# ADSP-SC83xW_HPC register map
Vendor: Analog Devices; Series: ADSP-SC83xW_HPC; File version: 3.0.3.517
CPU: 
Registers are 32-bit, read-write, reset 0x0 unless marked. A register's access mark holds for its fields unless they carry their own. Offsets are from the block's base; [hi:lo] are bit positions; 'fields as' and 'values as' point back to an identical list.

## PCG0 — Precision Clock Generator
Base 0x310C9000
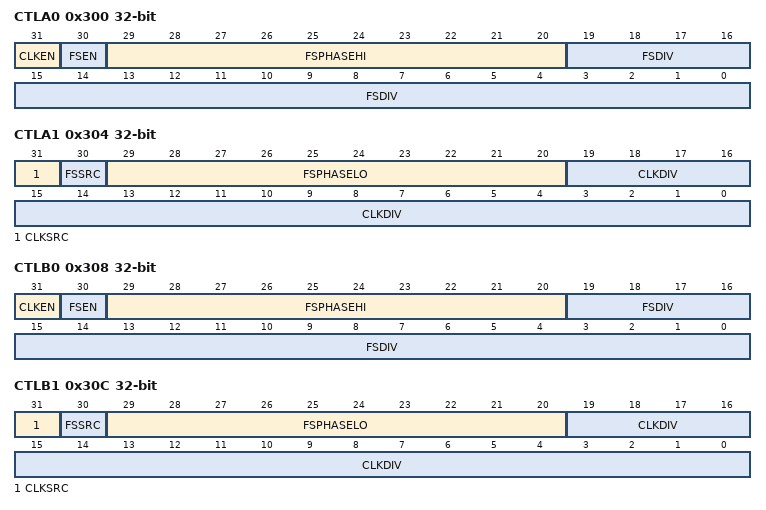
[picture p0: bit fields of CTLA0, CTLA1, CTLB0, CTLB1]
0x300 CTLA0 — Precision Clock A Control 0 Register
  [31] CLKEN — Clock Enable
  [30] FSEN — Frame Sync Enable
  [29:20] FSPHASEHI range 0x00000000..0x000003FF — Phase for Frame Sync High
  [19:0] FSDIV — Frame Sync Divider
0x304 CTLA1 — Precision Clock A Control 1 Register
  [31] CLKSRC — Clock Source
  [30] FSSRC — Frame Sync Source
  [29:20] FSPHASELO range 0x00000000..0x000003FF — Phase for Frame Sync Low
  [19:0] CLKDIV range 0x00000000..0x000FFFFF — Clock Divisor
0x308 CTLB0 — Precision Clock B Control 0 Register
  fields as CTLA0
0x30C CTLB1 — Precision Clock B Control 1 Register
  fields as CTLA1
0x310 PW1 — Precision Clock Pulse Width Control 1 Register
  [17] INVFSB range 0x00000000..0x00000001 — Active Low Frame Sync Select for Frame in Bypass PCG B
  [31:16] FSB range 0x00000000..0x0000FFFF — Pulse Width for Frame Sync PCG B
  [16] STROBEB range 0x00000000..0x00000001 — One Shot Frame Sync Bypass Mode PCG B
  [1] INVFSA range 0x00000000..0x00000001 — Active Low Frame Sync Select for Frame Sync in Bypass Mode
  [15:0] FSA range 0x00000000..0x0000FFFF — Pulse Width for Frame Sync PCG A
  [0] STROBEA range 0x00000000..0x00000001 — One Shot Frame Sync PCG A
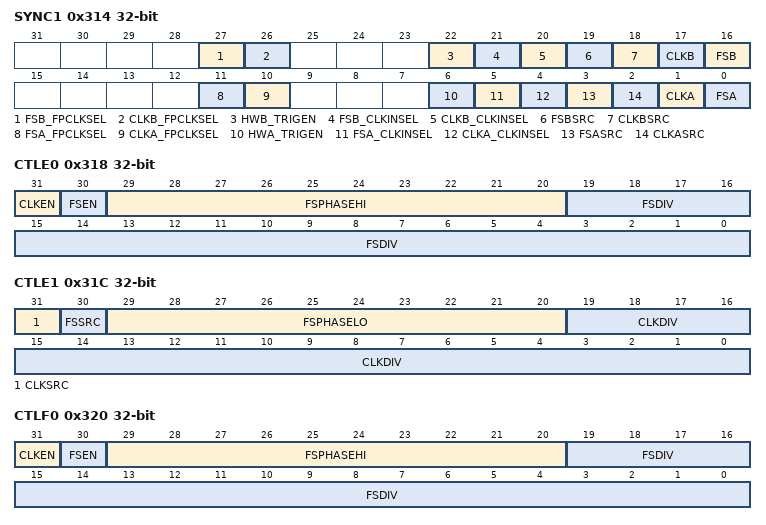
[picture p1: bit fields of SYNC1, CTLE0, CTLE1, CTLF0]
0x314 SYNC1 — Precision Clock Frame Sync Synchronization 1 Register
  [27] FSB_FPCLKSEL — Frame Sync B FracNPll Clock Select
  [26] CLKB_FPCLKSEL — Clock B FracNPll Clock Select
  [22] HWB_TRIGEN range 0x00000000..0x00000001 — Hardware Trigger Sync B Enable
  [21] FSB_CLKINSEL — CLKIN Source for FSB
  [20] CLKB_CLKINSEL — CLKIN Source for CLKB
  [19] FSBSRC — Frame Sync B Source
  [18] CLKBSRC — Clock B Source
  [17] CLKB — Clock B Enable
  [16] FSB — Frame Sync B Enable
  [11] FSA_FPCLKSEL — Frame Sync A FracNPll Clock Select
  [10] CLKA_FPCLKSEL — Clock A FracNPll Clock Select
  [6] HWA_TRIGEN range 0x00000000..0x00000001 — Hardware Trigger Sync A Enable
  [5] FSA_CLKINSEL — CLKIN Source for FSA
  [4] CLKA_CLKINSEL — CLKIN source for CLKA
  [3] FSASRC — Frame Sync Source
  [2] CLKASRC — Clock A Source
  [1] CLKA — Clock A Enable
  [0] FSA — Frame Sync A Enable
0x318 CTLE0 — Precision Clock E Control 0 Register
  fields as CTLA0
0x31C CTLE1 — Precision Clock E Control 1 Register
  fields as CTLA1
0x320 CTLF0 — Precision Clock F Control 0 Register
  fields as CTLA0
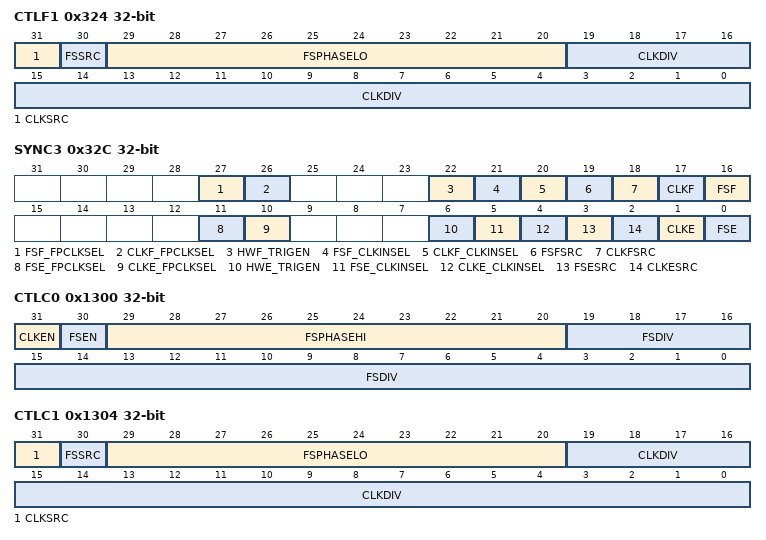
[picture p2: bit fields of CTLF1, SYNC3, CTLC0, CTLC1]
0x324 CTLF1 — Precision Clock F Control 1 Register
  fields as CTLA1
0x328 PW3 — Precision Clock Pulse Width Control 3 Register
  [17] INVFSF range 0x00000000..0x00000001 — Active Low Frame Sync Select for Frame Sync in Bypass Mode
  [31:16] FSF range 0x00000000..0x0000FFFF — Pulse Width for Frame Sync PCG F
  [16] STROBEF range 0x00000000..0x00000001 — One Shot Frame Sync PCG D
  [1] INVFSE range 0x00000000..0x00000001 — Active Low Frame Sync Select for Frame Sync in Bypass Mode
  [15:0] FSE range 0x00000000..0x0000FFFF — Pulse Width for Frame Sync PCG E
  [0] STROBEE range 0x00000000..0x00000001 — One Shot Frame Sync PCG E
0x32C SYNC3 — Precision Clock Frame Sync Synchronization 3 Register
  [27] FSF_FPCLKSEL — Frame Sync F FracNPll Clock Select
  [26] CLKF_FPCLKSEL — Clock F FracNPll Clock Select
  [22] HWF_TRIGEN range 0x00000000..0x00000001 — Hardware Trigger Sync F Enable
  [21] FSF_CLKINSEL — CLKIN Source for FSF
  [20] CLKF_CLKINSEL — CLKIN Source for CLKF
  [19] FSFSRC — Frame Sync F Source
  [18] CLKFSRC — Clock F Source
  [17] CLKF — Clock F Enable
  [16] FSF — Frame Sync F Enable
  [11] FSE_FPCLKSEL — Frame Sync E FracNPll Clock Select
  [10] CLKE_FPCLKSEL — Clock E FracNPll Clock Select
  [6] HWE_TRIGEN range 0x00000000..0x00000001 — Hardware Trigger Sync E Enable
  [5] FSE_CLKINSEL — CLKIN Source for FSE
  [4] CLKE_CLKINSEL — CLKIN Source for CLKE
  [3] FSESRC — Frame Sync Source
  [2] CLKESRC — Clock E Source
  [1] CLKE — Clock E Enable
  [0] FSE — Frame Sync E Enable
0x1300 CTLC0 — Precision Clock C Control 0 Register
  fields as CTLA0
0x1304 CTLC1 — Precision Clock C Control 1 Register
  fields as CTLA1
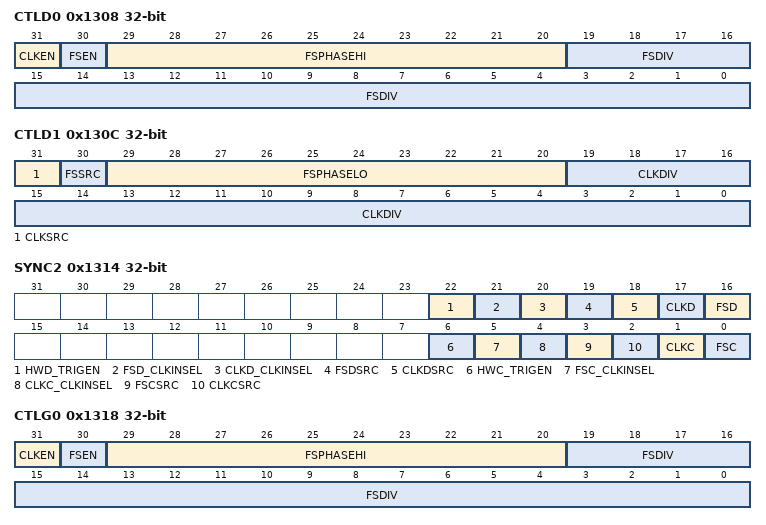
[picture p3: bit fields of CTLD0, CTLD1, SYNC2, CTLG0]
0x1308 CTLD0 — Precision Clock D Control 0 Register
  fields as CTLA0
0x130C CTLD1 — Precision Clock D Control 1 Register
  fields as CTLA1
0x1310 PW2 — Precision Clock Pulse Width Control 2 Register
  [17] INVFSD range 0x00000000..0x00000001 — Active Low Frame Sync Select for Frame Sync in Bypass Mode
  [31:16] FSD range 0x00000000..0x0000FFFF — Pulse Width for Frame Sync PCG D
  [16] STROBED range 0x00000000..0x00000001 — One Shot Frame Sync PCG D
  [1] INVFSC range 0x00000000..0x00000001 — Active Low Frame Sync Select for Frame Sync in Bypass Mode
  [15:0] FSC range 0x00000000..0x0000FFFF — Pulse Width for Frame Sync PCG C
  [0] STROBEC range 0x00000000..0x00000001 — One Shot Frame Sync PCG C
0x1314 SYNC2 — Precision Clock Frame Sync Synchronization 2 Register
  [22] HWD_TRIGEN range 0x00000000..0x00000001 — Hardware Trigger Sync D Enable
  [21] FSD_CLKINSEL — CLKIN Source for FSD
  [20] CLKD_CLKINSEL — CLKIN Source for CLKD
  [19] FSDSRC — Frame Sync D Source
  [18] CLKDSRC — Clock D Source
  [17] CLKD — Clock D Enable
  [16] FSD — Frame Sync D Enable
  [6] HWC_TRIGEN range 0x00000000..0x00000001 — Hardware Trigger Sync C Enable
  [5] FSC_CLKINSEL — CLKIN Source for FSC
  [4] CLKC_CLKINSEL — CLKIN Source for CLKC
  [3] FSCSRC — Frame Sync Source
  [2] CLKCSRC — Clock C Source
  [1] CLKC — Clock C Enable
  [0] FSC — Frame Sync C Enable
0x1318 CTLG0 — Precision Clock G Control 0 Register
  fields as CTLA0
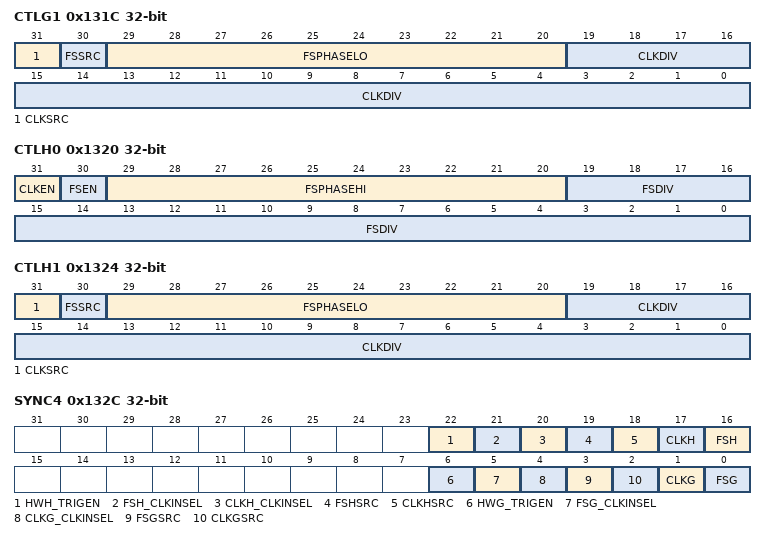
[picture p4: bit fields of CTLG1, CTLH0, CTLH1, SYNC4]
0x131C CTLG1 — Precision Clock G Control 1 Register
  fields as CTLA1
0x1320 CTLH0 — Precision Clock H Control 0 Register
  fields as CTLA0
0x1324 CTLH1 — Precision Clock H Control 1 Register
  fields as CTLA1
0x1328 PW4 — Precision Clock Pulse Width Control 4 Register
  [17] INVFSH range 0x00000000..0x00000001 — Active Low Frame Sync Select for Frame Sync in Bypass Mode
  [31:16] FSH range 0x00000000..0x0000FFFF — Pulse Width for Frame Sync PCG H
  [16] STROBEH range 0x00000000..0x00000001 — One Shot Frame Sync PCG H
  [1] INVFSG range 0x00000000..0x00000001 — Active Low Frame Sync Select for Frame Sync in Bypass Mode
  [15:0] FSG range 0x00000000..0x0000FFFF — Pulse Width for Frame Sync PCG G
  [0] STROBEG range 0x00000000..0x00000001 — One Shot Frame Sync PCG G
0x132C SYNC4 — Precision Clock Frame Sync Synchronization 4 Register
  [22] HWH_TRIGEN range 0x00000000..0x00000001 — Hardware Trigger Sync H Enable
  [21] FSH_CLKINSEL — CLKIN Source for FSH
  [20] CLKH_CLKINSEL — CLKIN Source for CLKH
  [19] FSHSRC — Frame Sync H Source
  [18] CLKHSRC — Clock H Source
  [17] CLKH — Clock H Enable
  [16] FSH — Frame Sync H Enable
  [6] HWG_TRIGEN range 0x00000000..0x00000001 — Hardware Trigger Sync G Enable
  [5] FSG_CLKINSEL — CLKIN Source for FSG
  [4] CLKG_CLKINSEL — CLKIN Source for CLKG
  [3] FSGSRC — Frame Sync Source
  [2] CLKGSRC — Clock G Source
  [1] CLKG — Clock G Enable
  [0] FSG — Frame Sync G Enable
